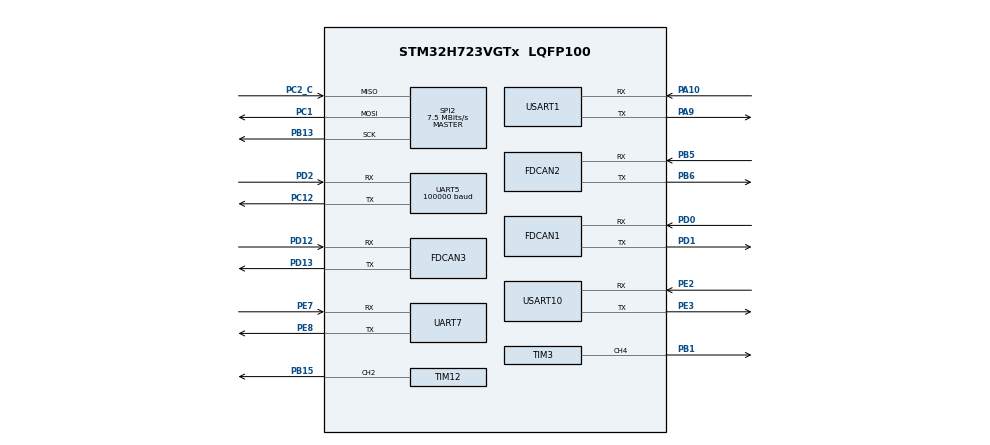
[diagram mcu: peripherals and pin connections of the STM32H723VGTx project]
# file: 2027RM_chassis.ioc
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CORTEX_M7.CPU_ICache=Disabled
CORTEX_M7.default_mode_Activation=1
Dma.Request0=SPI2_RX
Dma.Request1=SPI2_TX
Dma.Request2=UART5_RX
Dma.Request3=UART7_RX
Dma.Request4=UART7_TX
Dma.Request5=USART1_TX
Dma.Request6=USART10_RX
Dma.SPI2_RX.0.Direction=DMA_PERIPH_TO_MEMORY
Dma.SPI2_RX.0.EventEnable=DISABLE
Dma.SPI2_RX.0.FIFOMode=DMA_FIFOMODE_DISABLE
Dma.SPI2_RX.0.Instance=DMA1_Stream0
Dma.SPI2_RX.0.MemDataAlignment=DMA_MDATAALIGN_BYTE
Dma.SPI2_RX.0.MemInc=DMA_MINC_ENABLE
Dma.SPI2_RX.0.Mode=DMA_NORMAL
Dma.SPI2_RX.0.PeriphDataAlignment=DMA_PDATAALIGN_BYTE
Dma.SPI2_RX.0.PeriphInc=DMA_PINC_DISABLE
Dma.SPI2_RX.0.Polarity=HAL_DMAMUX_REQ_GEN_RISING
Dma.SPI2_RX.0.Priority=DMA_PRIORITY_VERY_HIGH
Dma.SPI2_RX.0.RequestNumber=1
Dma.SPI2_RX.0.SignalID=NONE
Dma.SPI2_RX.0.SyncEnable=DISABLE
Dma.SPI2_RX.0.SyncPolarity=HAL_DMAMUX_SYNC_NO_EVENT
Dma.SPI2_RX.0.SyncRequestNumber=1
Dma.SPI2_RX.0.SyncSignalID=NONE
Dma.SPI2_TX.1.Direction=DMA_MEMORY_TO_PERIPH
Dma.SPI2_TX.1.EventEnable=DISABLE
Dma.SPI2_TX.1.FIFOMode=DMA_FIFOMODE_DISABLE
Dma.SPI2_TX.1.Instance=DMA1_Stream2
Dma.SPI2_TX.1.MemDataAlignment=DMA_MDATAALIGN_BYTE
Dma.SPI2_TX.1.MemInc=DMA_MINC_ENABLE
Dma.SPI2_TX.1.Mode=DMA_NORMAL
Dma.SPI2_TX.1.PeriphDataAlignment=DMA_PDATAALIGN_BYTE
Dma.SPI2_TX.1.PeriphInc=DMA_PINC_DISABLE
Dma.SPI2_TX.1.Polarity=HAL_DMAMUX_REQ_GEN_RISING
Dma.SPI2_TX.1.Priority=DMA_PRIORITY_HIGH
Dma.SPI2_TX.1.RequestNumber=1
Dma.SPI2_TX.1.SignalID=NONE
Dma.SPI2_TX.1.SyncEnable=DISABLE
Dma.SPI2_TX.1.SyncPolarity=HAL_DMAMUX_SYNC_NO_EVENT
Dma.SPI2_TX.1.SyncRequestNumber=1
Dma.SPI2_TX.1.SyncSignalID=NONE
Dma.UART5_RX.2.Direction=DMA_PERIPH_TO_MEMORY
Dma.UART5_RX.2.EventEnable=DISABLE
Dma.UART5_RX.2.FIFOMode=DMA_FIFOMODE_DISABLE
Dma.UART5_RX.2.Instance=DMA1_Stream4
Dma.UART5_RX.2.MemDataAlignment=DMA_MDATAALIGN_BYTE
Dma.UART5_RX.2.MemInc=DMA_MINC_ENABLE
Dma.UART5_RX.2.Mode=DMA_CIRCULAR
Dma.UART5_RX.2.PeriphDataAlignment=DMA_PDATAALIGN_BYTE
Dma.UART5_RX.2.PeriphInc=DMA_PINC_DISABLE
Dma.UART5_RX.2.Polarity=HAL_DMAMUX_REQ_GEN_RISING
Dma.UART5_RX.2.Priority=DMA_PRIORITY_LOW
Dma.UART5_RX.2.RequestNumber=1
Dma.UART5_RX.2.SignalID=NONE
Dma.UART5_RX.2.SyncEnable=DISABLE
Dma.UART5_RX.2.SyncPolarity=HAL_DMAMUX_SYNC_NO_EVENT
Dma.UART5_RX.2.SyncRequestNumber=1
Dma.UART5_RX.2.SyncSignalID=NONE
Dma.UART7_RX.3.Direction=DMA_PERIPH_TO_MEMORY
Dma.UART7_RX.3.EventEnable=DISABLE
Dma.UART7_RX.3.FIFOMode=DMA_FIFOMODE_DISABLE
Dma.UART7_RX.3.Instance=DMA2_Stream6
Dma.UART7_RX.3.MemDataAlignment=DMA_MDATAALIGN_BYTE
Dma.UART7_RX.3.MemInc=DMA_MINC_ENABLE
Dma.UART7_RX.3.Mode=DMA_NORMAL
Dma.UART7_RX.3.PeriphDataAlignment=DMA_PDATAALIGN_BYTE
Dma.UART7_RX.3.PeriphInc=DMA_PINC_DISABLE
Dma.UART7_RX.3.Polarity=HAL_DMAMUX_REQ_GEN_RISING
Dma.UART7_RX.3.Priority=DMA_PRIORITY_LOW
Dma.UART7_RX.3.RequestNumber=1
Dma.UART7_RX.3.SignalID=NONE
Dma.UART7_RX.3.SyncEnable=DISABLE
Dma.UART7_RX.3.SyncPolarity=HAL_DMAMUX_SYNC_NO_EVENT
Dma.UART7_RX.3.SyncRequestNumber=1
Dma.UART7_RX.3.SyncSignalID=NONE
Dma.UART7_TX.4.Direction=DMA_MEMORY_TO_PERIPH
Dma.UART7_TX.4.EventEnable=DISABLE
Dma.UART7_TX.4.FIFOMode=DMA_FIFOMODE_DISABLE
Dma.UART7_TX.4.Instance=DMA1_Stream1
Dma.UART7_TX.4.MemDataAlignment=DMA_MDATAALIGN_BYTE
Dma.UART7_TX.4.MemInc=DMA_MINC_ENABLE
Dma.UART7_TX.4.Mode=DMA_NORMAL
Dma.UART7_TX.4.PeriphDataAlignment=DMA_PDATAALIGN_BYTE
Dma.UART7_TX.4.PeriphInc=DMA_PINC_DISABLE
Dma.UART7_TX.4.Polarity=HAL_DMAMUX_REQ_GEN_RISING
Dma.UART7_TX.4.Priority=DMA_PRIORITY_LOW
Dma.UART7_TX.4.RequestNumber=1
Dma.UART7_TX.4.SignalID=NONE
Dma.UART7_TX.4.SyncEnable=DISABLE
Dma.UART7_TX.4.SyncPolarity=HAL_DMAMUX_SYNC_NO_EVENT
Dma.UART7_TX.4.SyncRequestNumber=1
Dma.UART7_TX.4.SyncSignalID=NONE
Dma.USART10_RX.6.Direction=DMA_PERIPH_TO_MEMORY
Dma.USART10_RX.6.EventEnable=DISABLE
Dma.USART10_RX.6.FIFOMode=DMA_FIFOMODE_DISABLE
Dma.USART10_RX.6.Instance=DMA1_Stream3
Dma.USART10_RX.6.MemDataAlignment=DMA_MDATAALIGN_BYTE
Dma.USART10_RX.6.MemInc=DMA_MINC_ENABLE
Dma.USART10_RX.6.Mode=DMA_NORMAL
Dma.USART10_RX.6.PeriphDataAlignment=DMA_PDATAALIGN_BYTE
Dma.USART10_RX.6.PeriphInc=DMA_PINC_DISABLE
Dma.USART10_RX.6.Polarity=HAL_DMAMUX_REQ_GEN_RISING
Dma.USART10_RX.6.Priority=DMA_PRIORITY_MEDIUM
Dma.USART10_RX.6.RequestNumber=1
Dma.USART10_RX.6.SignalID=NONE
Dma.USART10_RX.6.SyncEnable=DISABLE
Dma.USART10_RX.6.SyncPolarity=HAL_DMAMUX_SYNC_NO_EVENT
Dma.USART10_RX.6.SyncRequestNumber=1
Dma.USART10_RX.6.SyncSignalID=NONE
Dma.USART1_TX.5.Direction=DMA_MEMORY_TO_PERIPH
Dma.USART1_TX.5.EventEnable=DISABLE
Dma.USART1_TX.5.FIFOMode=DMA_FIFOMODE_DISABLE
Dma.USART1_TX.5.Instance=DMA2_Stream0
Dma.USART1_TX.5.MemDataAlignment=DMA_MDATAALIGN_BYTE
Dma.USART1_TX.5.MemInc=DMA_MINC_ENABLE
Dma.USART1_TX.5.Mode=DMA_NORMAL
Dma.USART1_TX.5.PeriphDataAlignment=DMA_PDATAALIGN_BYTE
Dma.USART1_TX.5.PeriphInc=DMA_PINC_DISABLE
Dma.USART1_TX.5.Polarity=HAL_DMAMUX_REQ_GEN_RISING
Dma.USART1_TX.5.Priority=DMA_PRIORITY_LOW
Dma.USART1_TX.5.RequestNumber=1
Dma.USART1_TX.5.SignalID=NONE
Dma.USART1_TX.5.SyncEnable=DISABLE
Dma.USART1_TX.5.SyncPolarity=HAL_DMAMUX_SYNC_NO_EVENT
Dma.USART1_TX.5.SyncRequestNumber=1
Dma.USART1_TX.5.SyncSignalID=NONE
FDCAN1.AutoRetransmission=ENABLE
FDCAN1.CalculateBaudRateNominal=1000000
FDCAN1.CalculateTimeBitNominal=1000
FDCAN1.CalculateTimeQuantumNominal=50.0
FDCAN1.DataPrescaler=1
FDCAN1.DataTimeSeg1=15
FDCAN1.DataTimeSeg2=4
FDCAN1.FrameFormat=FDCAN_FRAME_FD_BRS
FDCAN1.NominalPrescaler=5
FDCAN1.NominalSyncJumpWidth=4
FDCAN1.NominalTimeSeg1=15
FDCAN1.NominalTimeSeg2=4
FDCAN1.ProtocolException=ENABLE
FDCAN1.RxFifo0ElmtSize=FDCAN_DATA_BYTES_64
FDCAN1.RxFifo0ElmtsNbr=16
FDCAN1.RxFifo1ElmtSize=FDCAN_DATA_BYTES_64
FDCAN1.StdFiltersNbr=1
FDCAN1.TxElmtSize=FDCAN_DATA_BYTES_64
FDCAN1.TxFifoQueueElmtsNbr=8
FDCAN2.AutoRetransmission=ENABLE
FDCAN2.CalculateBaudRateNominal=1000000
FDCAN2.CalculateTimeBitNominal=1000
FDCAN2.CalculateTimeQuantumNominal=50.0
FDCAN2.DataPrescaler=5
FDCAN2.DataTimeSeg1=14
FDCAN2.DataTimeSeg2=5
FDCAN2.MessageRAMOffset=512
FDCAN2.NominalPrescaler=5
FDCAN2.NominalSyncJumpWidth=4
FDCAN2.NominalTimeSeg1=14
FDCAN2.NominalTimeSeg2=5
FDCAN2.RxFifo0ElmtsNbr=0
FDCAN2.RxFifo1ElmtsNbr=8
FDCAN2.StdFiltersNbr=1
FDCAN2.TxFifoQueueElmtsNbr=3
FDCAN3.AutoRetransmission=ENABLE
FDCAN3.CalculateBaudRateNominal=1000000
FDCAN3.CalculateTimeBitNominal=1000
FDCAN3.CalculateTimeQuantumNominal=50.0
FDCAN3.DataPrescaler=5
FDCAN3.DataTimeSeg1=14
FDCAN3.DataTimeSeg2=5
FDCAN3.MessageRAMOffset=1709
FDCAN3.NominalPrescaler=5
FDCAN3.NominalSyncJumpWidth=1
FDCAN3.NominalTimeSeg1=14
FDCAN3.NominalTimeSeg2=5
FDCAN3.RxFifo0ElmtsNbr=4
FDCAN3.StdFiltersNbr=1
FDCAN3.TxElmtSize=FDCAN_DATA_BYTES_24
FDCAN3.TxFifoQueueElmtsNbr=4
FREERTOS.Tasks01=defaultTask,24,128,StartDefaultTask,Default,NULL,Dynamic,NULL,NULL;Chassis_Task,32,512,chassis_task,Default,NULL,Dynamic,NULL,NULL;IMU_task,48,1024,imu_task,Default,NULL,Dynamic,NULL,NULL;Talk_Task,24,128,Talk_Task_start,Default,NULL,Dynamic,NULL,NULL
Mcu.Family=STM32H7
Mcu.Name=STM32H723VGTx
Mcu.Package=LQFP100
NVIC.DMA1_Stream0_IRQn=true\:5\:0\:false\:false\:true\:true\:false\:true\:true
NVIC.DMA1_Stream1_IRQn=true\:5\:0\:false\:false\:true\:true\:false\:true\:true
NVIC.DMA1_Stream2_IRQn=true\:5\:0\:false\:false\:true\:true\:false\:true\:true
NVIC.DMA1_Stream3_IRQn=true\:5\:0\:false\:false\:true\:true\:false\:true\:true
NVIC.DMA1_Stream4_IRQn=true\:5\:0\:false\:false\:true\:true\:false\:true\:true
NVIC.DMA2_Stream0_IRQn=true\:5\:0\:false\:false\:true\:false\:false\:true\:true
NVIC.DMA2_Stream6_IRQn=true\:5\:0\:false\:false\:true\:false\:false\:true\:true
NVIC.FDCAN1_IT0_IRQn=true\:5\:0\:false\:false\:true\:true\:true\:true\:true
NVIC.FDCAN2_IT0_IRQn=true\:5\:0\:false\:false\:true\:true\:true\:true\:true
NVIC.FDCAN3_IT0_IRQn=true\:5\:0\:false\:false\:true\:true\:true\:true\:true
NVIC.PriorityGroup=NVIC_PRIORITYGROUP_4
NVIC.SPI2_IRQn=true\:5\:0\:false\:false\:true\:true\:false\:true\:true
NVIC.TIM4_IRQn=true\:15\:0\:false\:false\:true\:false\:false\:true\:true
NVIC.TimeBase=TIM4_IRQn
NVIC.TimeBaseIP=TIM4
NVIC.UART5_IRQn=true\:5\:0\:false\:false\:true\:true\:true\:true\:true
NVIC.UART7_IRQn=true\:5\:0\:false\:false\:true\:true\:true\:true\:true
NVIC.USART10_IRQn=true\:5\:0\:false\:false\:true\:true\:true\:true\:true
NVIC.USART1_IRQn=true\:5\:0\:false\:false\:true\:true\:true\:true\:true
PA10.Mode=Asynchronous
PA10.Signal=USART1_RX
PA9.Mode=Asynchronous
PA9.Signal=USART1_TX
PB1.Signal=S_TIM3_CH4
PB13.Mode=Full_Duplex_Master
PB13.Signal=SPI2_SCK
PB15.Signal=S_TIM12_CH2
PB5.Mode=FDCAN_Activate
PB5.Signal=FDCAN2_RX
PB6.Mode=FDCAN_Activate
PB6.Signal=FDCAN2_TX
PC1.Mode=Full_Duplex_Master
PC1.Signal=SPI2_MOSI
PC12.Mode=Asynchronous
PC12.Signal=UART5_TX
PC2_C.Mode=Full_Duplex_Master
PC2_C.Signal=SPI2_MISO
PD0.GPIO_Speed=GPIO_SPEED_FREQ_VERY_HIGH
PD0.Mode=FDCAN_Activate
PD0.Signal=FDCAN1_RX
PD1.GPIO_Speed=GPIO_SPEED_FREQ_VERY_HIGH
PD1.Mode=FDCAN_Activate
PD1.Signal=FDCAN1_TX
PD12.Mode=FDCAN_Activate
PD12.Signal=FDCAN3_RX
PD13.Mode=FDCAN_Activate
PD13.Signal=FDCAN3_TX
PD2.Mode=Asynchronous
PD2.Signal=UART5_RX
PE2.Mode=Asynchronous
PE2.Signal=USART10_RX
PE3.Mode=Asynchronous
PE3.Signal=USART10_TX
PE7.Mode=Asynchronous
PE7.Signal=UART7_RX
PE8.Mode=Asynchronous
PE8.Signal=UART7_TX
PH0-OSC_IN.Mode=HSE-External-Oscillator
PH0-OSC_IN.Signal=RCC_OSC_IN
PH1-OSC_OUT.Mode=HSE-External-Oscillator
PH1-OSC_OUT.Signal=RCC_OSC_OUT
ProjectManager.HeapSize=0x200
ProjectManager.StackSize=0x400
ProjectManager.TargetToolchain=MDK-ARM V5.32
RCC.ADCFreq_Value=100000000
RCC.APB1Freq_Value=120000000
RCC.APB2Freq_Value=120000000
RCC.APB3Freq_Value=120000000
RCC.APB4Freq_Value=120000000
RCC.CortexFreq_Value=480000000
RCC.D1PPRE=RCC_APB3_DIV2
RCC.D2PPRE1=RCC_APB1_DIV2
RCC.D2PPRE2=RCC_APB2_DIV2
RCC.D3PPRE=RCC_APB4_DIV2
RCC.DIVM1=2
RCC.DIVM2=24
RCC.DIVN1=40
RCC.DIVN2=200
RCC.DIVP1=1
RCC.FDCANCLockSelection=RCC_FDCANCLKSOURCE_PLL2
RCC.HCLKFreq_Value=240000000
RCC.HPRE=RCC_HCLK_DIV2
RCC.HSE_VALUE=24000000
RCC.PLL2FRACN=0
RCC.PLLFRACN=0
RCC.PLLSourceVirtual=RCC_PLLSOURCE_HSE
RCC.SYSCLKFreq_VALUE=480000000
RCC.SYSCLKSource=RCC_SYSCLKSOURCE_PLLCLK
RCC.USBFreq_Value=240000000
SH.S_TIM12_CH2.0=TIM12_CH2,PWM Generation2 CH2
SH.S_TIM3_CH4.0=TIM3_CH4,PWM Generation4 CH4
SPI2.BaudRatePrescaler=SPI_BAUDRATEPRESCALER_32
SPI2.CLKPhase=SPI_PHASE_2EDGE
SPI2.CLKPolarity=SPI_POLARITY_HIGH
SPI2.CalculateBaudRate=7.5 MBits/s
SPI2.DataSize=SPI_DATASIZE_8BIT
SPI2.Direction=SPI_DIRECTION_2LINES
SPI2.Mode=SPI_MODE_MASTER
SPI2.VirtualType=VM_MASTER
TIM12.Channel-PWM\ Generation2\ CH2=TIM_CHANNEL_2
TIM3.Channel-PWM\ Generation4\ CH4=TIM_CHANNEL_4
TIM5.Prescaler=240-1
TIM7.Prescaler=240-1
UART5.BaudRate=100000
UART5.StopBits=UART_STOPBITS_2
UART5.WordLength=WORDLENGTH_9B
USART1.VirtualMode-Asynchronous=VM_ASYNC
USART10.VirtualMode=VM_ASYNC
VP_FREERTOS_VS_CMSIS_V2.Mode=CMSIS_V2
VP_MEMORYMAP_VS_MEMORYMAP.Mode=CurAppReg
VP_SYS_VS_tim4.Mode=TIM4
VP_TIM5_VS_ClockSourceINT.Mode=Internal
VP_TIM7_VS_ClockSourceINT.Mode=Enable_Timer
board=custom

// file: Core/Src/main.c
/* USER CODE BEGIN Header */
/**
  ******************************************************************************
  * @file           : main.c
  * @brief          : Main program body
  ******************************************************************************
  * @attention
  *
  * Copyright (c) 2026 STMicroelectronics.
  * All rights reserved.
  *
  * This software is licensed under terms that can be found in the LICENSE file
  * in the root directory of this software component.
  * If no LICENSE file comes with this software, it is provided AS-IS.
  *
  ******************************************************************************
  */
/* USER CODE END Header */
#include "main.h"
#include "FreeRTOS.h"
#include "cmsis_os2.h"
#include "dma.h"
#include "fdcan.h"
#include "spi.h"
#include "tim.h"
#include "usart.h"
#include "gpio.h"

/* USER CODE BEGIN Includes */
#include "chassis_task.h"
#include "CAN_cmd_damiao.h"
#include "motor.h"
#include "bsp_can.h"
/* USER CODE END Includes */

void SystemClock_Config(void);
void PeriphCommonClock_Config(void);
static void MPU_Config(void);
void MX_FREERTOS_Init(void);

/* USER CODE BEGIN 0 */
extern Chassis_s CHASSIS;
/* USER CODE END 0 */

int main(void)
{

  /* MPU Configuration--------------------------------------------------------*/
  MPU_Config();

  /* MCU Configuration--------------------------------------------------------*/

  /* Reset of all peripherals, Initializes the Flash interface and the Systick. */
  HAL_Init();

  /* Configure the system clock */
  SystemClock_Config();

  /* Configure the peripherals common clocks */
  PeriphCommonClock_Config();

  /* Initialize all configured peripherals */
  MX_GPIO_Init();
  MX_DMA_Init();
  MX_FDCAN1_Init();
  MX_FDCAN2_Init();
  MX_FDCAN3_Init();
  MX_SPI2_Init();
  MX_TIM3_Init();
  MX_TIM5_Init();
  MX_TIM7_Init();
  MX_TIM12_Init();
  MX_UART5_Init();
  MX_UART7_Init();
  MX_USART1_UART_Init();
  MX_USART10_UART_Init();
  /* USER CODE BEGIN 2 */
  /* CPU cycle counter for measured task periods/execution times. */
  CoreDebug->DEMCR |= CoreDebug_DEMCR_TRCENA_Msk;
  DWT->CYCCNT = 0U;
  DWT->CTRL |= DWT_CTRL_CYCCNTENA_Msk;
  __DSB();
  __ISB();
		FDCAN1_Config();
	FDCAN2_Config();
  FDCAN3_Config();

//	MotorInit(&CHASSIS.joint_motor[2],
//          3, JOINT_CAN, DM_8009,
//          J0_DIRECTION, 1, DM_MODE_MIT);

//DmEnable(&CHASSIS.joint_motor[2]);

//	MotorInit(&CHASSIS.joint_motor[3],
//          4, JOINT_CAN, DM_8009,
//          J0_DIRECTION, 1, DM_MODE_MIT);

//DmEnable(&CHASSIS.joint_motor[3]);

//	MotorInit(&CHASSIS.joint_motor[0],
//          1, JOINT_CAN, DM_8009,
//          J0_DIRECTION, 1, DM_MODE_MIT);

//DmEnable(&CHASSIS.joint_motor[0]);

//	MotorInit(&CHASSIS.joint_motor[1],
//          2, JOINT_CAN, DM_8009,
//          J0_DIRECTION, 1, DM_MODE_MIT);

//DmEnable(&CHASSIS.joint_motor[1]);
//HAL_Delay(10);
//ChassisInit();
//HAL_Delay(10);
  /* USER CODE END 2 */

  /* Init scheduler */
  osKernelInitialize();  /* Call init function for freertos objects (in cmsis_os2.c) */
  MX_FREERTOS_Init();

  /* Start scheduler */
  osKernelStart();

  /* We should never get here as control is now taken by the scheduler */

  /* Infinite loop */
  while (1)
  {
		/////////////////腿长读取
		// 1. 掉线自动重使能保护（防止电机后上电未使能）
//      for (uint8_t i = 0; i < 4; i++) {
//          if (CHASSIS.joint_motor[i].fdb.state == 0) {
//              DmEnable(&CHASSIS.joint_motor[i]);
//              HAL_Delay(1);
//          }
//      }
//			// 2. 更新电机反馈并解算虚拟腿长 L0 和角度 Phi0
//      for (uint8_t i = 0; i < 4; i++) {
//          GetMotorMeasure(&CHASSIS.joint_motor[i]);
//      }
//
//		UpdateLegStatus();
//
//			// 3. 发送 0 力矩指令（既让腿保持无力可手掰，又触发达妙电机回传下一帧位置数据）
//      for (uint8_t i = 0; i < 4; i++) {
//          CHASSIS.joint_motor[i].set.tor = 0.0f;
//      }
//      DmMitCtrlTorque(&CHASSIS.joint_motor[0]);
//      DmMitCtrlTorque(&CHASSIS.joint_motor[1]);
//      HAL_Delay(1); // 分批发送，防止 FDCAN TX FIFO 溢出丢包
//      DmMitCtrlTorque(&CHASSIS.joint_motor[2]);
//      DmMitCtrlTorque(&CHASSIS.joint_motor[3]);

			//////////////电机测试
//      GetMotorMeasure(&CHASSIS.joint_motor[1]);
//      GetMotorMeasure(&CHASSIS.joint_motor[0]);
//      GetMotorMeasure(&CHASSIS.joint_motor[3]);
//		  GetMotorMeasure(&CHASSIS.joint_motor[2]);
//
//      CHASSIS.joint_motor[0].set.tor = 0.0f;
//		  CHASSIS.joint_motor[1].set.tor = 0.0f;
//   		CHASSIS.joint_motor[2].set.tor = 0.0f;
//		  CHASSIS.joint_motor[3].set.tor = 0.0f;
//      DmMitCtrlTorque(&CHASSIS.joint_motor[0]);
//      DmMitCtrlTorque(&CHASSIS.joint_motor[1]);
//      DmMitCtrlTorque(&CHASSIS.joint_motor[2]);
//      DmMitCtrlTorque(&CHASSIS.joint_motor[3]);
//
	//	FDCAN1_UpdateDebug();
 //     HAL_Delay(1);
  }
}

void SystemClock_Config(void)
{
  RCC_OscInitTypeDef RCC_OscInitStruct = {0};
  RCC_ClkInitTypeDef RCC_ClkInitStruct = {0};

  /** Supply configuration update enable
  */
  HAL_PWREx_ConfigSupply(PWR_LDO_SUPPLY);

  /** Configure the main internal regulator output voltage
  */
  __HAL_PWR_VOLTAGESCALING_CONFIG(PWR_REGULATOR_VOLTAGE_SCALE0);

  while(!__HAL_PWR_GET_FLAG(PWR_FLAG_VOSRDY)) {}

  /** Initializes the RCC Oscillators according to the specified parameters
  * in the RCC_OscInitTypeDef structure.
  */
  RCC_OscInitStruct.OscillatorType = RCC_OSCILLATORTYPE_HSE;
  RCC_OscInitStruct.HSEState = RCC_HSE_ON;
  RCC_OscInitStruct.PLL.PLLState = RCC_PLL_ON;
  RCC_OscInitStruct.PLL.PLLSource = RCC_PLLSOURCE_HSE;
  RCC_OscInitStruct.PLL.PLLM = 2;
  RCC_OscInitStruct.PLL.PLLN = 40;
  RCC_OscInitStruct.PLL.PLLP = 1;
  RCC_OscInitStruct.PLL.PLLQ = 2;
  RCC_OscInitStruct.PLL.PLLR = 2;
  RCC_OscInitStruct.PLL.PLLRGE = RCC_PLL1VCIRANGE_3;
  RCC_OscInitStruct.PLL.PLLVCOSEL = RCC_PLL1VCOWIDE;
  RCC_OscInitStruct.PLL.PLLFRACN = 0;
  if (HAL_RCC_OscConfig(&RCC_OscInitStruct) != HAL_OK)
  {
    Error_Handler();
  }

  /** Initializes the CPU, AHB and APB buses clocks
  */
  RCC_ClkInitStruct.ClockType = RCC_CLOCKTYPE_HCLK|RCC_CLOCKTYPE_SYSCLK
                              |RCC_CLOCKTYPE_PCLK1|RCC_CLOCKTYPE_PCLK2
                              |RCC_CLOCKTYPE_D3PCLK1|RCC_CLOCKTYPE_D1PCLK1;
  RCC_ClkInitStruct.SYSCLKSource = RCC_SYSCLKSOURCE_PLLCLK;
  RCC_ClkInitStruct.SYSCLKDivider = RCC_SYSCLK_DIV1;
  RCC_ClkInitStruct.AHBCLKDivider = RCC_HCLK_DIV2;
  RCC_ClkInitStruct.APB3CLKDivider = RCC_APB3_DIV2;
  RCC_ClkInitStruct.APB1CLKDivider = RCC_APB1_DIV2;
  RCC_ClkInitStruct.APB2CLKDivider = RCC_APB2_DIV2;
  RCC_ClkInitStruct.APB4CLKDivider = RCC_APB4_DIV2;

  if (HAL_RCC_ClockConfig(&RCC_ClkInitStruct, FLASH_LATENCY_3) != HAL_OK)
  {
    Error_Handler();
  }
}

void PeriphCommonClock_Config(void)
{
  RCC_PeriphCLKInitTypeDef PeriphClkInitStruct = {0};

  /** Initializes the peripherals clock
  */
  PeriphClkInitStruct.PeriphClockSelection = RCC_PERIPHCLK_FDCAN;
  PeriphClkInitStruct.PLL2.PLL2M = 24;
  PeriphClkInitStruct.PLL2.PLL2N = 200;
  PeriphClkInitStruct.PLL2.PLL2P = 2;
  PeriphClkInitStruct.PLL2.PLL2Q = 2;
  PeriphClkInitStruct.PLL2.PLL2R = 2;
  PeriphClkInitStruct.PLL2.PLL2RGE = RCC_PLL2VCIRANGE_0;
  PeriphClkInitStruct.PLL2.PLL2VCOSEL = RCC_PLL2VCOMEDIUM;
  PeriphClkInitStruct.PLL2.PLL2FRACN = 0;
  PeriphClkInitStruct.FdcanClockSelection = RCC_FDCANCLKSOURCE_PLL2;
  if (HAL_RCCEx_PeriphCLKConfig(&PeriphClkInitStruct) != HAL_OK)
  {
    Error_Handler();
  }
}

 /* MPU Configuration */

void MPU_Config(void)
{
  MPU_Region_InitTypeDef MPU_InitStruct = {0};

  /* Disables the MPU */
  HAL_MPU_Disable();

  /** Initializes and configures the Region and the memory to be protected
  */
  MPU_InitStruct.Enable = MPU_REGION_ENABLE;
  MPU_InitStruct.Number = MPU_REGION_NUMBER0;
  MPU_InitStruct.BaseAddress = 0x0;
  MPU_InitStruct.Size = MPU_REGION_SIZE_4GB;
  MPU_InitStruct.SubRegionDisable = 0x87;
  MPU_InitStruct.TypeExtField = MPU_TEX_LEVEL0;
  MPU_InitStruct.AccessPermission = MPU_REGION_NO_ACCESS;
  MPU_InitStruct.DisableExec = MPU_INSTRUCTION_ACCESS_DISABLE;
  MPU_InitStruct.IsShareable = MPU_ACCESS_SHAREABLE;
  MPU_InitStruct.IsCacheable = MPU_ACCESS_NOT_CACHEABLE;
  MPU_InitStruct.IsBufferable = MPU_ACCESS_NOT_BUFFERABLE;

  HAL_MPU_ConfigRegion(&MPU_InitStruct);
  /* Enables the MPU */
  HAL_MPU_Enable(MPU_PRIVILEGED_DEFAULT);

}

void HAL_TIM_PeriodElapsedCallback(TIM_HandleTypeDef *htim)
{
  if (htim->Instance == TIM4)
  {
    HAL_IncTick();
  }
}

void Error_Handler(void)
{
  __disable_irq();
  while (1)
  {
  }
}
